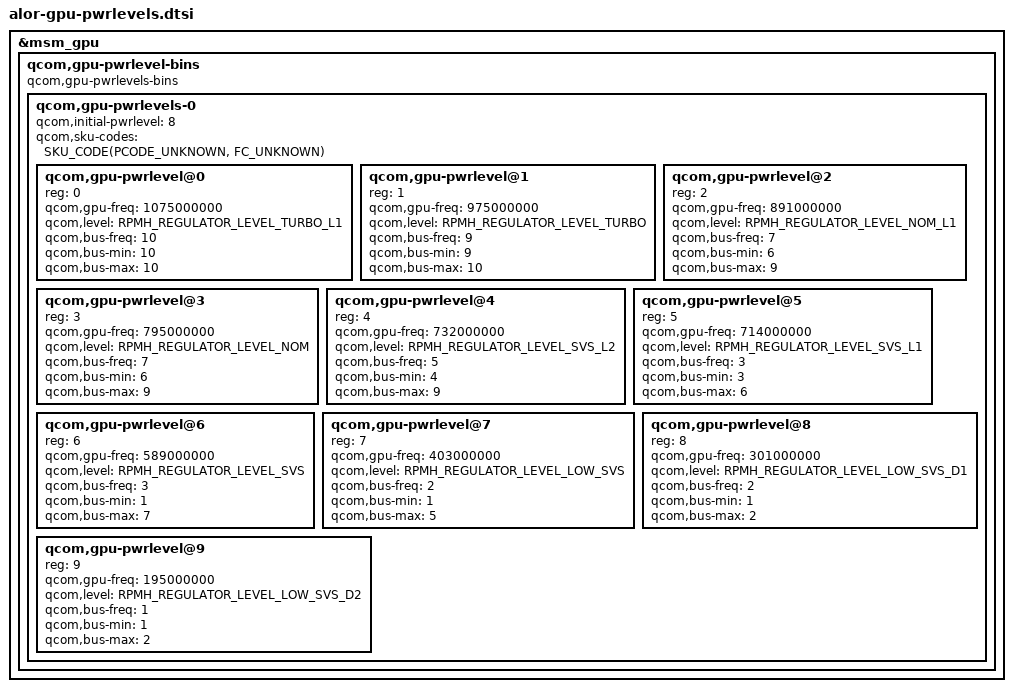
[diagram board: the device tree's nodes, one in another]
// SPDX-License-Identifier: BSD-3-Clause
/*
 * Copyright (c) Qualcomm Technologies, Inc. and/or its subsidiaries.
 */

&msm_gpu {
	/* Power levels */
	qcom,gpu-pwrlevel-bins {
		#address-cells = <1>;
		#size-cells = <0>;

		compatible = "qcom,gpu-pwrlevels-bins";

		/* Keep the pwrlevel bins sorted on the highest qcom,gpu-freq */
		qcom,gpu-pwrlevels-0 {
			#address-cells = <1>;
			#size-cells = <0>;

			qcom,initial-pwrlevel = <8>;
			qcom,sku-codes = <SKU_CODE(PCODE_UNKNOWN, FC_UNKNOWN)>;

			/* TURBO_L1 */
			qcom,gpu-pwrlevel@0 {
				reg = <0>;
				qcom,gpu-freq = <1075000000>;
				qcom,level = <RPMH_REGULATOR_LEVEL_TURBO_L1>;

				qcom,bus-freq = <10>;
				qcom,bus-min = <10>;
				qcom,bus-max = <10>;
			};

			/* TURBO */
			qcom,gpu-pwrlevel@1 {
				reg = <1>;
				qcom,gpu-freq = <975000000>;
				qcom,level = <RPMH_REGULATOR_LEVEL_TURBO>;

				qcom,bus-freq = <9>;
				qcom,bus-min = <9>;
				qcom,bus-max = <10>;
			};

			/* NOM_L1 */
			qcom,gpu-pwrlevel@2 {
				reg = <2>;
				qcom,gpu-freq = <891000000>;
				qcom,level = <RPMH_REGULATOR_LEVEL_NOM_L1>;

				qcom,bus-freq = <7>;
				qcom,bus-min = <6>;
				qcom,bus-max = <9>;
			};

			/* NOM */
			qcom,gpu-pwrlevel@3 {
				reg = <3>;
				qcom,gpu-freq = <795000000>;
				qcom,level = <RPMH_REGULATOR_LEVEL_NOM>;

				qcom,bus-freq = <7>;
				qcom,bus-min = <6>;
				qcom,bus-max = <9>;
			};

			/* SVS_L2 */
			qcom,gpu-pwrlevel@4 {
				reg = <4>;
				qcom,gpu-freq = <732000000>;
				qcom,level = <RPMH_REGULATOR_LEVEL_SVS_L2>;

				qcom,bus-freq = <5>;
				qcom,bus-min = <4>;
				qcom,bus-max = <9>;
			};

			/* SVS_L1 */
			qcom,gpu-pwrlevel@5 {
				reg = <5>;
				qcom,gpu-freq = <714000000>;
				qcom,level = <RPMH_REGULATOR_LEVEL_SVS_L1>;

				qcom,bus-freq = <3>;
				qcom,bus-min = <3>;
				qcom,bus-max = <6>;
			};

			/* SVS */
			qcom,gpu-pwrlevel@6 {
				reg = <6>;
				qcom,gpu-freq = <589000000>;
				qcom,level = <RPMH_REGULATOR_LEVEL_SVS>;

				qcom,bus-freq = <3>;
				qcom,bus-min = <1>;
				qcom,bus-max = <7>;
			};

			/* Low_SVS */
			qcom,gpu-pwrlevel@7 {
				reg = <7>;
				qcom,gpu-freq = <403000000>;
				qcom,level = <RPMH_REGULATOR_LEVEL_LOW_SVS>;

				qcom,bus-freq = <2>;
				qcom,bus-min = <1>;
				qcom,bus-max = <5>;
			};

			/* Low_SVS_D1 */
			qcom,gpu-pwrlevel@8 {
				reg = <8>;
				qcom,gpu-freq = <301000000>;
				qcom,level = <RPMH_REGULATOR_LEVEL_LOW_SVS_D1>;

				qcom,bus-freq = <2>;
				qcom,bus-min = <1>;
				qcom,bus-max = <2>;
			};

			/* Low_SVS_D2 */
			qcom,gpu-pwrlevel@9 {
				reg = <9>;
				qcom,gpu-freq = <195000000>;
				qcom,level = <RPMH_REGULATOR_LEVEL_LOW_SVS_D2>;

				qcom,bus-freq = <1>;
				qcom,bus-min = <1>;
				qcom,bus-max = <2>;
			};
		};
	};
};
